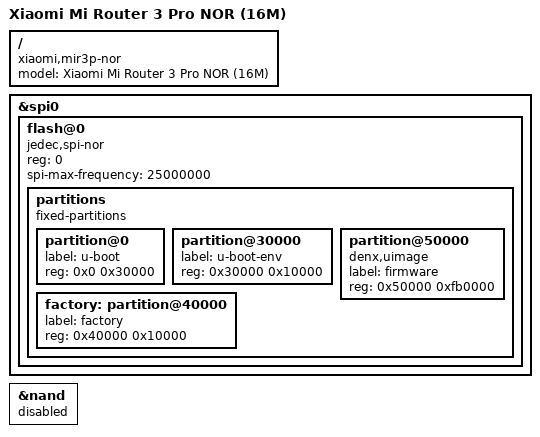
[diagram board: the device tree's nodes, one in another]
// SPDX-License-Identifier: GPL-2.0-or-later OR MIT
/dts-v1/;

#include "mt7621_xiaomi_mir3p.dts"

/ {
	compatible = "xiaomi,mir3p-nor", "mediatek,mt7621-soc";
	model = "Xiaomi Mi Router 3 Pro NOR (16M)";
};

&spi0 {
	status = "okay";

	flash@0 {
		compatible = "jedec,spi-nor";
		reg = <0>;
		spi-max-frequency = <25000000>;

		partitions {
			compatible = "fixed-partitions";
			#address-cells = <1>;
			#size-cells = <1>;

			partition@0 {
				label = "u-boot";
				reg = <0x0 0x30000>;
			};

			partition@30000 {
				label = "u-boot-env";
				reg = <0x30000 0x10000>;
			};

			factory: partition@40000 {
				label = "factory";
				reg = <0x40000 0x10000>;
			};

			partition@50000 {
				compatible = "denx,uimage";
				label = "firmware";
				reg = <0x50000 0xfb0000>;
			};
		};
	};
};

&nand {
	status = "disabled";
	/delete-node/ partitions;
};
